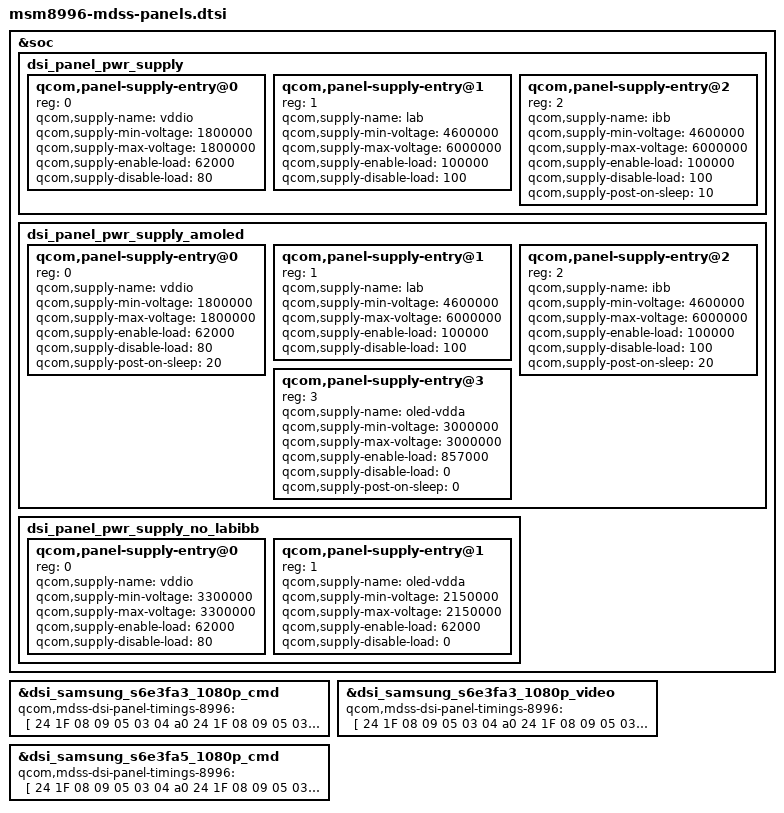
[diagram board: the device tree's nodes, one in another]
/* Copyright (c) 2015, The Linux Foundation. All rights reserved.
 *
 * This program is free software; you can redistribute it and/or modify
 * it under the terms of the GNU General Public License version 2 and
 * only version 2 as published by the Free Software Foundation.
 *
 * This program is distributed in the hope that it will be useful,
 * but WITHOUT ANY WARRANTY; without even the implied warranty of
 * MERCHANTABILITY or FITNESS FOR A PARTICULAR PURPOSE.  See the
 * GNU General Public License for more details.
 */

#include "dsi-panel-samsung_s6e3fa3_1080p_cmd.dtsi"  //guozhiming modify for lcd 2015-10-15
#include "dsi-panel-samsung_s6e3fa3_1080p_video.dtsi"
#include "dsi-panel-samsung_s6e3fa5_1080p_cmd.dtsi"

&soc {
	dsi_panel_pwr_supply: dsi_panel_pwr_supply {
		#address-cells = <1>;
		#size-cells = <0>;

		qcom,panel-supply-entry@0 {
			reg = <0>;
			qcom,supply-name = "vddio";
			qcom,supply-min-voltage = <1800000>;
			qcom,supply-max-voltage = <1800000>;
			qcom,supply-enable-load = <62000>;
			qcom,supply-disable-load = <80>;
		};

		qcom,panel-supply-entry@1 {
			reg = <1>;
			qcom,supply-name = "lab";
			qcom,supply-min-voltage = <4600000>;
			qcom,supply-max-voltage = <6000000>;
			qcom,supply-enable-load = <100000>;
			qcom,supply-disable-load = <100>;
		};

		qcom,panel-supply-entry@2 {
			reg = <2>;
			qcom,supply-name = "ibb";
			qcom,supply-min-voltage = <4600000>;
			qcom,supply-max-voltage = <6000000>;
			qcom,supply-enable-load = <100000>;
			qcom,supply-disable-load = <100>;
			qcom,supply-post-on-sleep = <10>;
		};
	};
};

&soc {
	dsi_panel_pwr_supply_amoled: dsi_panel_pwr_supply_amoled {
		#address-cells = <1>;
		#size-cells = <0>;

		qcom,panel-supply-entry@0 {
			reg = <0>;
			qcom,supply-name = "vddio";
			qcom,supply-min-voltage = <1800000>;
			qcom,supply-max-voltage = <1800000>;
			qcom,supply-enable-load = <62000>;
			qcom,supply-disable-load = <80>;
			qcom,supply-post-on-sleep = <20>;
		};

		qcom,panel-supply-entry@1 {
			reg = <1>;
			qcom,supply-name = "lab";
			qcom,supply-min-voltage = <4600000>;
			qcom,supply-max-voltage = <6000000>;
			qcom,supply-enable-load = <100000>;
			qcom,supply-disable-load = <100>;
		};

		qcom,panel-supply-entry@2 {
			reg = <2>;
			qcom,supply-name = "ibb";
			qcom,supply-min-voltage = <4600000>;
			qcom,supply-max-voltage = <6000000>;
			qcom,supply-enable-load = <100000>;
			qcom,supply-disable-load = <100>;
			qcom,supply-post-on-sleep = <20>;
		};

		qcom,panel-supply-entry@3 {
			reg = <3>;
			qcom,supply-name = "oled-vdda";
			qcom,supply-min-voltage = <3000000>;
			qcom,supply-max-voltage = <3000000>;
			qcom,supply-enable-load = <857000>;
			qcom,supply-disable-load = <0>;
			qcom,supply-post-on-sleep = <0>;
		};
	};
};

&soc {
	dsi_panel_pwr_supply_no_labibb: dsi_panel_pwr_supply_no_labibb {
		#address-cells = <1>;
		#size-cells = <0>;

		qcom,panel-supply-entry@0 {
			reg = <0>;
			qcom,supply-name = "vddio";
			//qcom,supply-min-voltage = <1800000>; //guozhiming modify for lcd 2015-10-15
			//qcom,supply-max-voltage = <1800000>;
			qcom,supply-min-voltage = <3300000>;
			qcom,supply-max-voltage = <3300000>;
			qcom,supply-enable-load = <62000>;
			qcom,supply-disable-load = <80>;
			//qcom,supply-post-on-sleep = <20>; yankelong del，don't need in 15801
		};

		qcom,panel-supply-entry@1 {
			reg = <1>;
			qcom,supply-name = "oled-vdda";
			qcom,supply-min-voltage = <2150000>;
			qcom,supply-max-voltage = <2150000>;
			qcom,supply-enable-load = <62000>;
			qcom,supply-disable-load = <0>;
		};
	};
};
//guozhiming modify for lcd 2015-10-15
&dsi_samsung_s6e3fa3_1080p_cmd {
	qcom,mdss-dsi-panel-timings-8996 = [
       24 1F 08 09 05 03 04 a0
       24 1F 08 09 05 03 04 a0
       24 1F 08 09 05 03 04 a0
       24 1F 08 09 05 03 04 a0
       24 1B 08 09 05 03 04 a0];
};

&dsi_samsung_s6e3fa3_1080p_video {
       qcom,mdss-dsi-panel-timings-8996 = [
       24 1F 08 09 05 03 04 a0
       24 1F 08 09 05 03 04 a0
       24 1F 08 09 05 03 04 a0
       24 1F 08 09 05 03 04 a0
       24 1B 08 09 05 03 04 a0];
};

&dsi_samsung_s6e3fa5_1080p_cmd {
       qcom,mdss-dsi-panel-timings-8996 = [
       24 1F 08 09 05 03 04 a0
       24 1F 08 09 05 03 04 a0
       24 1F 08 09 05 03 04 a0
       24 1F 08 09 05 03 04 a0
       24 1B 08 09 05 03 04 a0];
};
